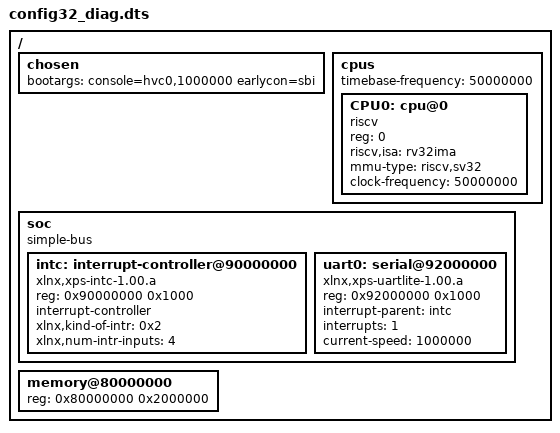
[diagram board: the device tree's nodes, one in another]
// SPDX-License-Identifier: GPL-2.0
// 诊断用:控制台走 hvc0(能正常到 shell),但保留 intc/uartlite 节点,
// 让 ttyUL0 作为普通 tty 设备存在 → 到 shell 后手动 echo >/dev/ttyUL0 单独测中断驱动 TX。
/dts-v1/;

/ {
  #address-cells = <1>;
  #size-cells = <1>;

  chosen {
      bootargs = "console=hvc0,1000000 earlycon=sbi";
  };

  cpus {
    #address-cells = <1>;
    #size-cells = <0>;
    timebase-frequency = <50000000>;
    CPU0: cpu@0 {
      device_type = "cpu";
      reg = <0>;
      status = "okay";
      compatible = "riscv";
      riscv,isa = "rv32ima";
      mmu-type = "riscv,sv32";
      clock-frequency = <50000000>;
    };
  };

  soc {
    #address-cells = <1>;
    #size-cells = <1>;
    compatible = "simple-bus";
    ranges;

    intc: interrupt-controller@90000000 {
        compatible = "xlnx,xps-intc-1.00.a";
        reg = <0x90000000 0x1000>;
        #interrupt-cells = <1>;
        interrupt-controller;
        xlnx,kind-of-intr = <0x2>;
        xlnx,num-intr-inputs = <4>;
    };

    uart0: serial@92000000 {
        compatible = "xlnx,xps-uartlite-1.00.a";
        reg = <0x92000000 0x1000>;
        interrupt-parent = <&intc>;
        interrupts = <1>;
        current-speed = <1000000>;
    };
  };

  memory@80000000 {
      device_type = "memory";
      reg = <0x80000000 0x2000000>;
  };
};
